VERSION "created by canmatrix"

NS_ :

BS_:

BU_: Host RT MTR EPS_C SEB HMI Any

BO_ 1 SAFETY_ESTOP_high: 0 Any

BO_ 1 SAFETY_ESTOP_low: 0 Any

BO_ 288 SYS_THROTTLE_STS_low: 2 MTR
 SG_ speed_mmps : 7|16@0- (1,0) [-500|3000] "" RT

BO_ 288 SYS_THROTTLE_STS_high: 2 MTR
 SG_ speed_mmps : 7|16@0- (1,0) [-500|3000] "" Host

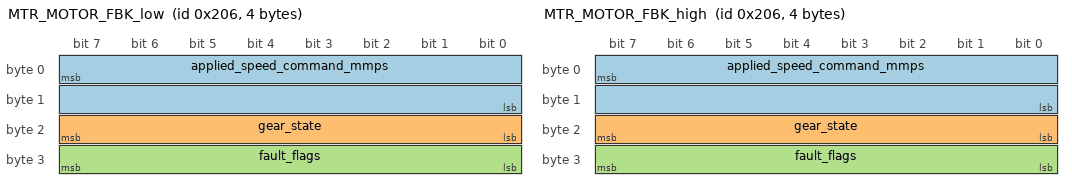
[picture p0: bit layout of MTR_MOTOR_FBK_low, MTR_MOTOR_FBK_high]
BO_ 518 MTR_MOTOR_FBK_low: 4 MTR
 SG_ applied_speed_command_mmps : 7|16@0- (1,0) [-500|3000] "" RT
 SG_ gear_state : 23|8@0+ (1,0) [0|3] "" RT
 SG_ fault_flags : 31|8@0+ (1,0) [0|255] "" RT

BO_ 518 MTR_MOTOR_FBK_high: 4 MTR
 SG_ applied_speed_command_mmps : 7|16@0- (1,0) [-500|3000] "" Host
 SG_ gear_state : 23|8@0+ (1,0) [0|3] "" Host
 SG_ fault_flags : 31|8@0+ (1,0) [0|255] "" Host

BO_ 516 RTA_DRIVE_CMD_low: 5 RT
 SG_ motor_speed_mmps : 7|32@0- (1,0) [-500|3000] "" MTR
 SG_ gear : 39|8@0+ (1,0) [0|3] "" MTR

BO_ 272 RTA_MODE_CMD_low: 1 RT
 SG_ mode : 7|8@0+ (1,0) [0|2] "" MTR

BO_ 2045 RTA_HEARTBEAT_low: 2 RT
 SG_ alive_ctr : 7|8@0+ (1,0) [0|255] "" MTR
 SG_ health_flags : 15|8@0+ (1,0) [0|255] "" MTR

BA_DEF_ BO_ "GenMsgCycleTime" INT 0 65535;

BA_ "GenMsgCycleTime" BO_ 288 10;
BA_ "GenMsgCycleTime" BO_ 288 10;
BA_ "GenMsgCycleTime" BO_ 518 20;
BA_ "GenMsgCycleTime" BO_ 518 20;
BA_ "GenMsgCycleTime" BO_ 516 10;
BA_ "GenMsgCycleTime" BO_ 272 1000;
BA_ "GenMsgCycleTime" BO_ 2045 500;

VAL_ 516 gear 0 "N" 1 "D" 2 "S" 3 "R";
